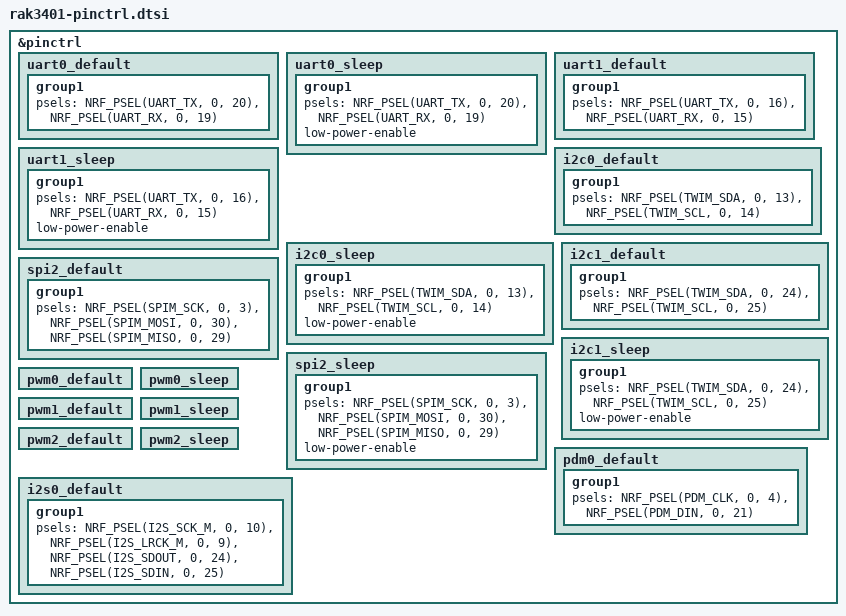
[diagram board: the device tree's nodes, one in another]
/*
 * SPDX-License-Identifier: Apache-2.0
 * Copyright (c) 2026 RAKwireless Technology Limited
 */

#include <zephyr/dt-bindings/pinctrl/nrf-pinctrl.h>

&pinctrl {
	uart0_default: uart0_default {
		group1 {
			psels = <NRF_PSEL(UART_TX, 0, 20)>,
				<NRF_PSEL(UART_RX, 0, 19)>;
		};
	};

	uart0_sleep: uart0_sleep {
		group1 {
			psels = <NRF_PSEL(UART_TX, 0, 20)>,
				<NRF_PSEL(UART_RX, 0, 19)>;
			low-power-enable;
		};
	};

	uart1_default: uart1_default {
		group1 {
			psels = <NRF_PSEL(UART_TX, 0, 16)>,
				<NRF_PSEL(UART_RX, 0, 15)>;
		};
	};

	uart1_sleep: uart1_sleep {
		group1 {
			psels = <NRF_PSEL(UART_TX, 0, 16)>,
				<NRF_PSEL(UART_RX, 0, 15)>;
			low-power-enable;
		};
	};

	i2c0_default: i2c0_default {
		group1 {
			psels = <NRF_PSEL(TWIM_SDA, 0, 13)>,
				<NRF_PSEL(TWIM_SCL, 0, 14)>;
		};
	};

	i2c0_sleep: i2c0_sleep {
		group1 {
			psels = <NRF_PSEL(TWIM_SDA, 0, 13)>,
				<NRF_PSEL(TWIM_SCL, 0, 14)>;
			low-power-enable;
		};
	};

	i2c1_default: i2c1_default {
		group1 {
			psels = <NRF_PSEL(TWIM_SDA, 0, 24)>,
				<NRF_PSEL(TWIM_SCL, 0, 25)>;
		};
	};

	i2c1_sleep: i2c1_sleep {
		group1 {
			psels = <NRF_PSEL(TWIM_SDA, 0, 24)>,
				<NRF_PSEL(TWIM_SCL, 0, 25)>;
			low-power-enable;
		};
	};

	spi2_default: spi2_default {
		group1 {
			psels = <NRF_PSEL(SPIM_SCK, 0, 3)>,
				<NRF_PSEL(SPIM_MOSI, 0, 30)>,
				<NRF_PSEL(SPIM_MISO, 0, 29)>;
		};
	};

	spi2_sleep: spi2_sleep {
		group1 {
			psels = <NRF_PSEL(SPIM_SCK, 0, 3)>,
				<NRF_PSEL(SPIM_MOSI, 0, 30)>,
				<NRF_PSEL(SPIM_MISO, 0, 29)>;
			low-power-enable;
		};
	};

	/*
	 * PWM pinctrl states are intentionally empty. board.c computes pin
	 * assignments at compile time from installed shield DT nodes and
	 * installs them via pinctrl_update_states() at boot.
	 */
	pwm0_default: pwm0_default {

	};

	pwm0_sleep: pwm0_sleep {

	};

	pwm1_default: pwm1_default {

	};

	pwm1_sleep: pwm1_sleep {

	};

	pwm2_default: pwm2_default {

	};

	pwm2_sleep: pwm2_sleep {

	};

	pdm0_default: pdm0_default {
		group1 {
			psels = <NRF_PSEL(PDM_CLK, 0, 4)>,
				<NRF_PSEL(PDM_DIN, 0, 21)>;
		};
	};

	i2s0_default: i2s0_default {
		group1 {
			psels = <NRF_PSEL(I2S_SCK_M, 0, 10)>,
				<NRF_PSEL(I2S_LRCK_M, 0, 9)>,
				<NRF_PSEL(I2S_SDOUT, 0, 24)>,
				<NRF_PSEL(I2S_SDIN, 0, 25)>;
		};
	};
};
